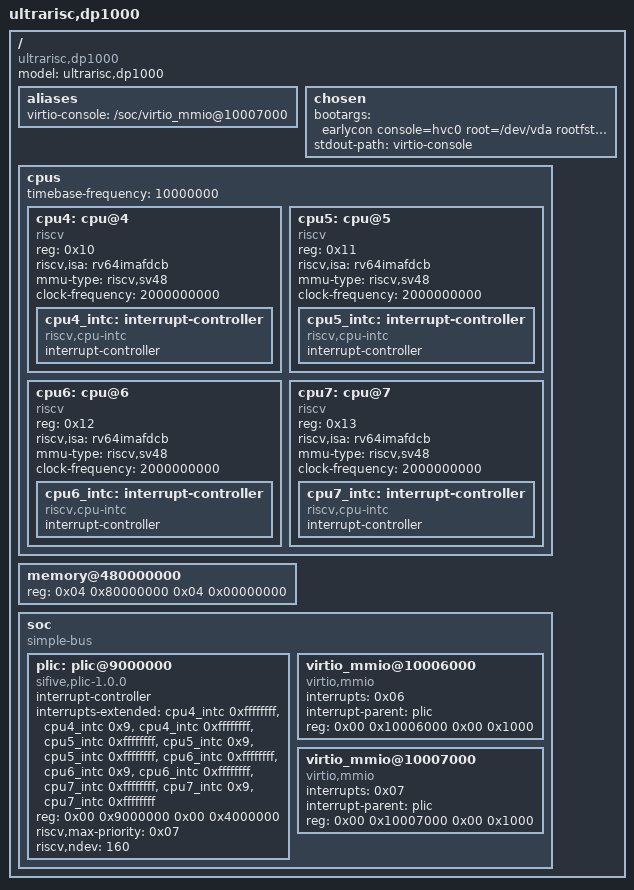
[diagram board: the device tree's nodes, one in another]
/dts-v1/;

/ {
	#address-cells = <0x02>;
	#size-cells = <0x02>;
	compatible = "ultrarisc,dp1000";
	model = "ultrarisc,dp1000";

    aliases {
		virtio-console = "/soc/virtio_mmio@10007000";
	};

	chosen {
		bootargs = "earlycon console=hvc0 root=/dev/vda rootfstype=ext4 rw rootwait";
		stdout-path = "virtio-console";
	};

	cpus {
		#address-cells = <0x01>;
		#size-cells = <0x00>;
		timebase-frequency = <10000000>;

	    cpu4: cpu@4 {
			device_type = "cpu";
			reg = <0x10>;
			status = "okay";
			compatible = "riscv";
			riscv,isa = "rv64imafdcb";
			mmu-type = "riscv,sv48";
			clock-frequency = <2000000000>;
			cpu4_intc:interrupt-controller {
				#address-cells = <0x01>;
				interrupt-controller;
				compatible = "riscv,cpu-intc";
				#interrupt-cells = <0x01>;
			};
		};
		cpu5: cpu@5 {
			device_type = "cpu";
			reg = <0x11>;
			status = "okay";
			compatible = "riscv";
			riscv,isa = "rv64imafdcb";
			mmu-type = "riscv,sv48";
			clock-frequency = <2000000000>;
			cpu5_intc:interrupt-controller {
				#address-cells = <0x01>;
				interrupt-controller;
				compatible = "riscv,cpu-intc";
				#interrupt-cells = <0x01>;
			};
		};
		cpu6: cpu@6 {
			device_type = "cpu";
			reg = <0x12>;
			status = "okay";
			compatible = "riscv";
			riscv,isa = "rv64imafdcb";
			mmu-type = "riscv,sv48";
			clock-frequency = <2000000000>;
			cpu6_intc:interrupt-controller {
				#address-cells = <0x01>;
				interrupt-controller;
				compatible = "riscv,cpu-intc";
				#interrupt-cells = <0x01>;
			};
		};
		cpu7: cpu@7 {
			device_type = "cpu";
			reg = <0x13>;
			status = "okay";
			compatible = "riscv";
			riscv,isa = "rv64imafdcb";
			mmu-type = "riscv,sv48";
			clock-frequency = <2000000000>;
			cpu7_intc:interrupt-controller {
				#address-cells = <0x01>;
				interrupt-controller;
				compatible = "riscv,cpu-intc";
				#interrupt-cells = <0x01>;
			};
		};
	};

	memory@480000000 {
		device_type = "memory";
		reg = <0x04 0x80000000 0x04 0x00000000>;
	};

	soc {
		#address-cells = <0x02>;
		#size-cells = <0x02>;
		compatible = "simple-bus";
		ranges;

		plic: plic@9000000 {
			#interrupt-cells = <1>;
			#address-cells = <0>;
			phandle = <0x01>;
			compatible = "sifive,plic-1.0.0";
			interrupt-controller;
			interrupts-extended = <&cpu4_intc 0xffffffff>, <&cpu4_intc 0x9>, <&cpu4_intc 0xffffffff>,
            <&cpu5_intc 0xffffffff>, <&cpu5_intc 0x9>, <&cpu5_intc 0xffffffff>,
            <&cpu6_intc 0xffffffff>, <&cpu6_intc 0x9>, <&cpu6_intc 0xffffffff>,
            <&cpu7_intc 0xffffffff>, <&cpu7_intc 0x9>, <&cpu7_intc 0xffffffff>;
			reg = <0x00 0x9000000 0x00 0x4000000>;
			riscv,max-priority = <0x07>;
			riscv,ndev = <160>;
		};

		virtio_mmio@10006000 {
			interrupts = <0x06>;
			interrupt-parent = <&plic>;
			reg = <0x00 0x10006000 0x00 0x1000>;
			compatible = "virtio,mmio";
		};

		virtio_mmio@10007000 {
			interrupts = <0x07>;
			interrupt-parent = <&plic>;
			reg = <0x00 0x10007000 0x00 0x1000>;
			compatible = "virtio,mmio";
		};
	};
};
